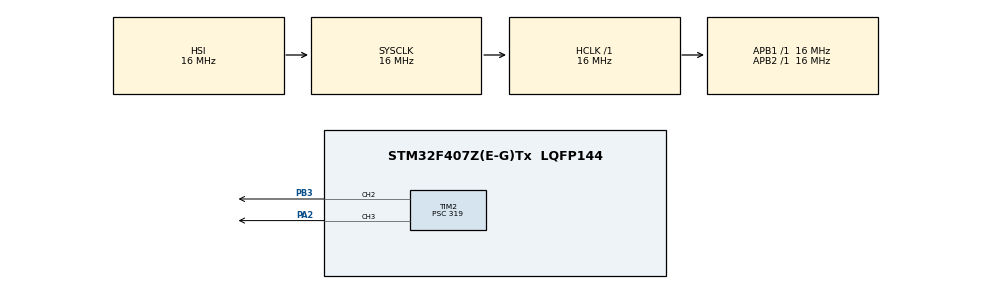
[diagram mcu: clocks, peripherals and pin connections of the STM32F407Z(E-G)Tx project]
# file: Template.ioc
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Mcu.Family=STM32F4
Mcu.Name=STM32F407Z(E-G)Tx
Mcu.Package=LQFP144
NVIC.PriorityGroup=NVIC_PRIORITYGROUP_4
PA13.Mode=Serial_Wire
PA13.Signal=SYS_JTMS-SWDIO
PA14.Mode=Serial_Wire
PA14.Signal=SYS_JTCK-SWCLK
PA2.Signal=S_TIM2_CH3
PB3.Signal=S_TIM2_CH2
ProjectManager.HeapSize=0x200
ProjectManager.StackSize=0x400
ProjectManager.TargetToolchain=MDK-ARM V5.32
RCC.AHBFreq_Value=16000000
RCC.APB1Freq_Value=16000000
RCC.APB2Freq_Value=16000000
RCC.CortexFreq_Value=16000000
RCC.HSE_VALUE=25000000
RCC.HSI_VALUE=16000000
RCC.LSE_VALUE=32768
RCC.SYSCLKFreq_VALUE=16000000
RCC.VCOOutputFreq_Value=192000000
SH.S_TIM2_CH2.0=TIM2_CH2,PWM Generation2 CH2
SH.S_TIM2_CH3.0=TIM2_CH3,PWM Generation3 CH3
TIM2.Channel-PWM\ Generation2\ CH2=TIM_CHANNEL_2
TIM2.Channel-PWM\ Generation3\ CH3=TIM_CHANNEL_3
TIM2.Period=999
TIM2.Prescaler=319
TIM2.Pulse-PWM\ Generation2\ CH2=25
TIM2.Pulse-PWM\ Generation3\ CH3=75
board=custom

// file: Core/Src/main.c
/* USER CODE BEGIN Header */
/**
  ******************************************************************************
  * @file           : main.c
  * @brief          : Main program body
  ******************************************************************************
  * @attention
  *
  * Copyright (c) 2025 STMicroelectronics.
  * All rights reserved.
  *
  * This software is licensed under terms that can be found in the LICENSE file
  * in the root directory of this software component.
  * If no LICENSE file comes with this software, it is provided AS-IS.
  *
  ******************************************************************************
  */
/* USER CODE END Header */
#include "main.h"
#include "tim.h"

/* USER CODE BEGIN Includes */
#include "keys.h"
/* USER CODE END Includes */

/* USER CODE BEGIN PV */
float SG90T180_ANGLE = 0;
float SG90B180_ANGLE = 90;
/* USER CODE END PV */

void SystemClock_Config(void);
/* USER CODE BEGIN PFP */
void SG90T180_SetAngle(float angle);
void SG90B180_SetAngle(float angle);
/* USER CODE END PFP */

int main(void)
{

  /* MCU Configuration--------------------------------------------------------*/

  /* Reset of all peripherals, Initializes the Flash interface and the Systick. */
  HAL_Init();

  /* Configure the system clock */
  SystemClock_Config();

  /* USER CODE BEGIN SysInit */
	Delay_Init();
  /* USER CODE END SysInit */

  /* Initialize all configured peripherals */
  MX_TIM2_Init();
  /* USER CODE BEGIN 2 */
	Keys_Init();
  /* USER CODE END 2 */

  /* Infinite loop */
  /* USER CODE BEGIN WHILE */
  while (1)
  {

		SG90T180_SetAngle(SG90T180_ANGLE);
		SG90B180_SetAngle(SG90B180_ANGLE);

		if (KeyA0_HasBeenClicked())	//KeyA0负责复位，即上舵机回归0度，下舵机回归90度。
		{
			SG90T180_ANGLE = 0;
			SG90B180_ANGLE = 90;
		}

		if (KeyA1_HasBeenClicked())	//KeyA1负责上舵机在0度与90度之间切换。
		{
			if (SG90T180_ANGLE == 0)
			{
				SG90T180_ANGLE = 90;
			}
			else
			{
				SG90T180_ANGLE = 0;
			}
		}

		if (KeyB0_HasBeenClicked())	//KeyB0负责下舵机向左转。
		{
			if(SG90B180_ANGLE == 180 || SG90B180_ANGLE == 90)
			{
				SG90B180_ANGLE -= 90;
			}
		}

		if (KeyB1_HasBeenClicked())	//KeyB1负责下舵机向右转。
		{
			if(SG90B180_ANGLE == 0 || SG90B180_ANGLE == 90)
			{
				SG90B180_ANGLE += 90;
			}
		}
    /* USER CODE END WHILE */

  }
}

void SystemClock_Config(void)
{
  RCC_OscInitTypeDef RCC_OscInitStruct = {0};
  RCC_ClkInitTypeDef RCC_ClkInitStruct = {0};

  /** Configure the main internal regulator output voltage
  */
  __HAL_RCC_PWR_CLK_ENABLE();
  __HAL_PWR_VOLTAGESCALING_CONFIG(PWR_REGULATOR_VOLTAGE_SCALE1);

  /** Initializes the RCC Oscillators according to the specified parameters
  * in the RCC_OscInitTypeDef structure.
  */
  RCC_OscInitStruct.OscillatorType = RCC_OSCILLATORTYPE_HSI;
  RCC_OscInitStruct.HSIState = RCC_HSI_ON;
  RCC_OscInitStruct.HSICalibrationValue = RCC_HSICALIBRATION_DEFAULT;
  RCC_OscInitStruct.PLL.PLLState = RCC_PLL_NONE;
  if (HAL_RCC_OscConfig(&RCC_OscInitStruct) != HAL_OK)
  {
    Error_Handler();
  }

  /** Initializes the CPU, AHB and APB buses clocks
  */
  RCC_ClkInitStruct.ClockType = RCC_CLOCKTYPE_HCLK|RCC_CLOCKTYPE_SYSCLK
                              |RCC_CLOCKTYPE_PCLK1|RCC_CLOCKTYPE_PCLK2;
  RCC_ClkInitStruct.SYSCLKSource = RCC_SYSCLKSOURCE_HSI;
  RCC_ClkInitStruct.AHBCLKDivider = RCC_SYSCLK_DIV1;
  RCC_ClkInitStruct.APB1CLKDivider = RCC_HCLK_DIV1;
  RCC_ClkInitStruct.APB2CLKDivider = RCC_HCLK_DIV1;

  if (HAL_RCC_ClockConfig(&RCC_ClkInitStruct, FLASH_LATENCY_0) != HAL_OK)
  {
    Error_Handler();
  }
}

/* USER CODE BEGIN 4 */
void SG90T180_SetAngle(float angle)
{
	__HAL_TIM_SetCompare(&htim2, TIM_CHANNEL_2, (double)angle/180.0 * 100.0 + 25);
}

void SG90B180_SetAngle(float angle)
{
	__HAL_TIM_SetCompare(&htim2, TIM_CHANNEL_3, (double)angle/180.0 * 100.0 + 25);
}
/* USER CODE END 4 */

void Error_Handler(void)
{
  __disable_irq();
  while (1)
  {
  }
}
